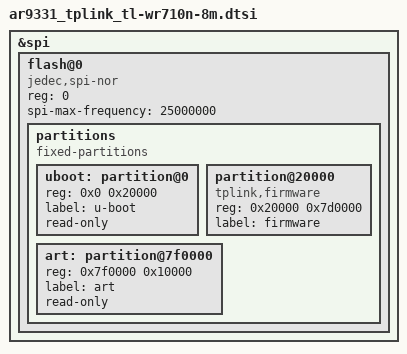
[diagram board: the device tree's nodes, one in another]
// SPDX-License-Identifier: GPL-2.0-or-later OR MIT

#include "ar9331_tplink_tl-wr710n.dtsi"

&spi {
	status = "okay";

	flash@0 {
		compatible = "jedec,spi-nor";
		reg = <0>;
		spi-max-frequency = <25000000>;

		partitions {
			compatible = "fixed-partitions";
			#address-cells = <1>;
			#size-cells = <1>;

			uboot: partition@0 {
				reg = <0x0 0x20000>;
				label = "u-boot";
				read-only;
			};

			partition@20000 {
				compatible = "tplink,firmware";
				reg = <0x20000 0x7d0000>;
				label = "firmware";
			};

			art: partition@7f0000 {
				reg = <0x7f0000 0x10000>;
				label = "art";
				read-only;
			};
		};
	};
};
